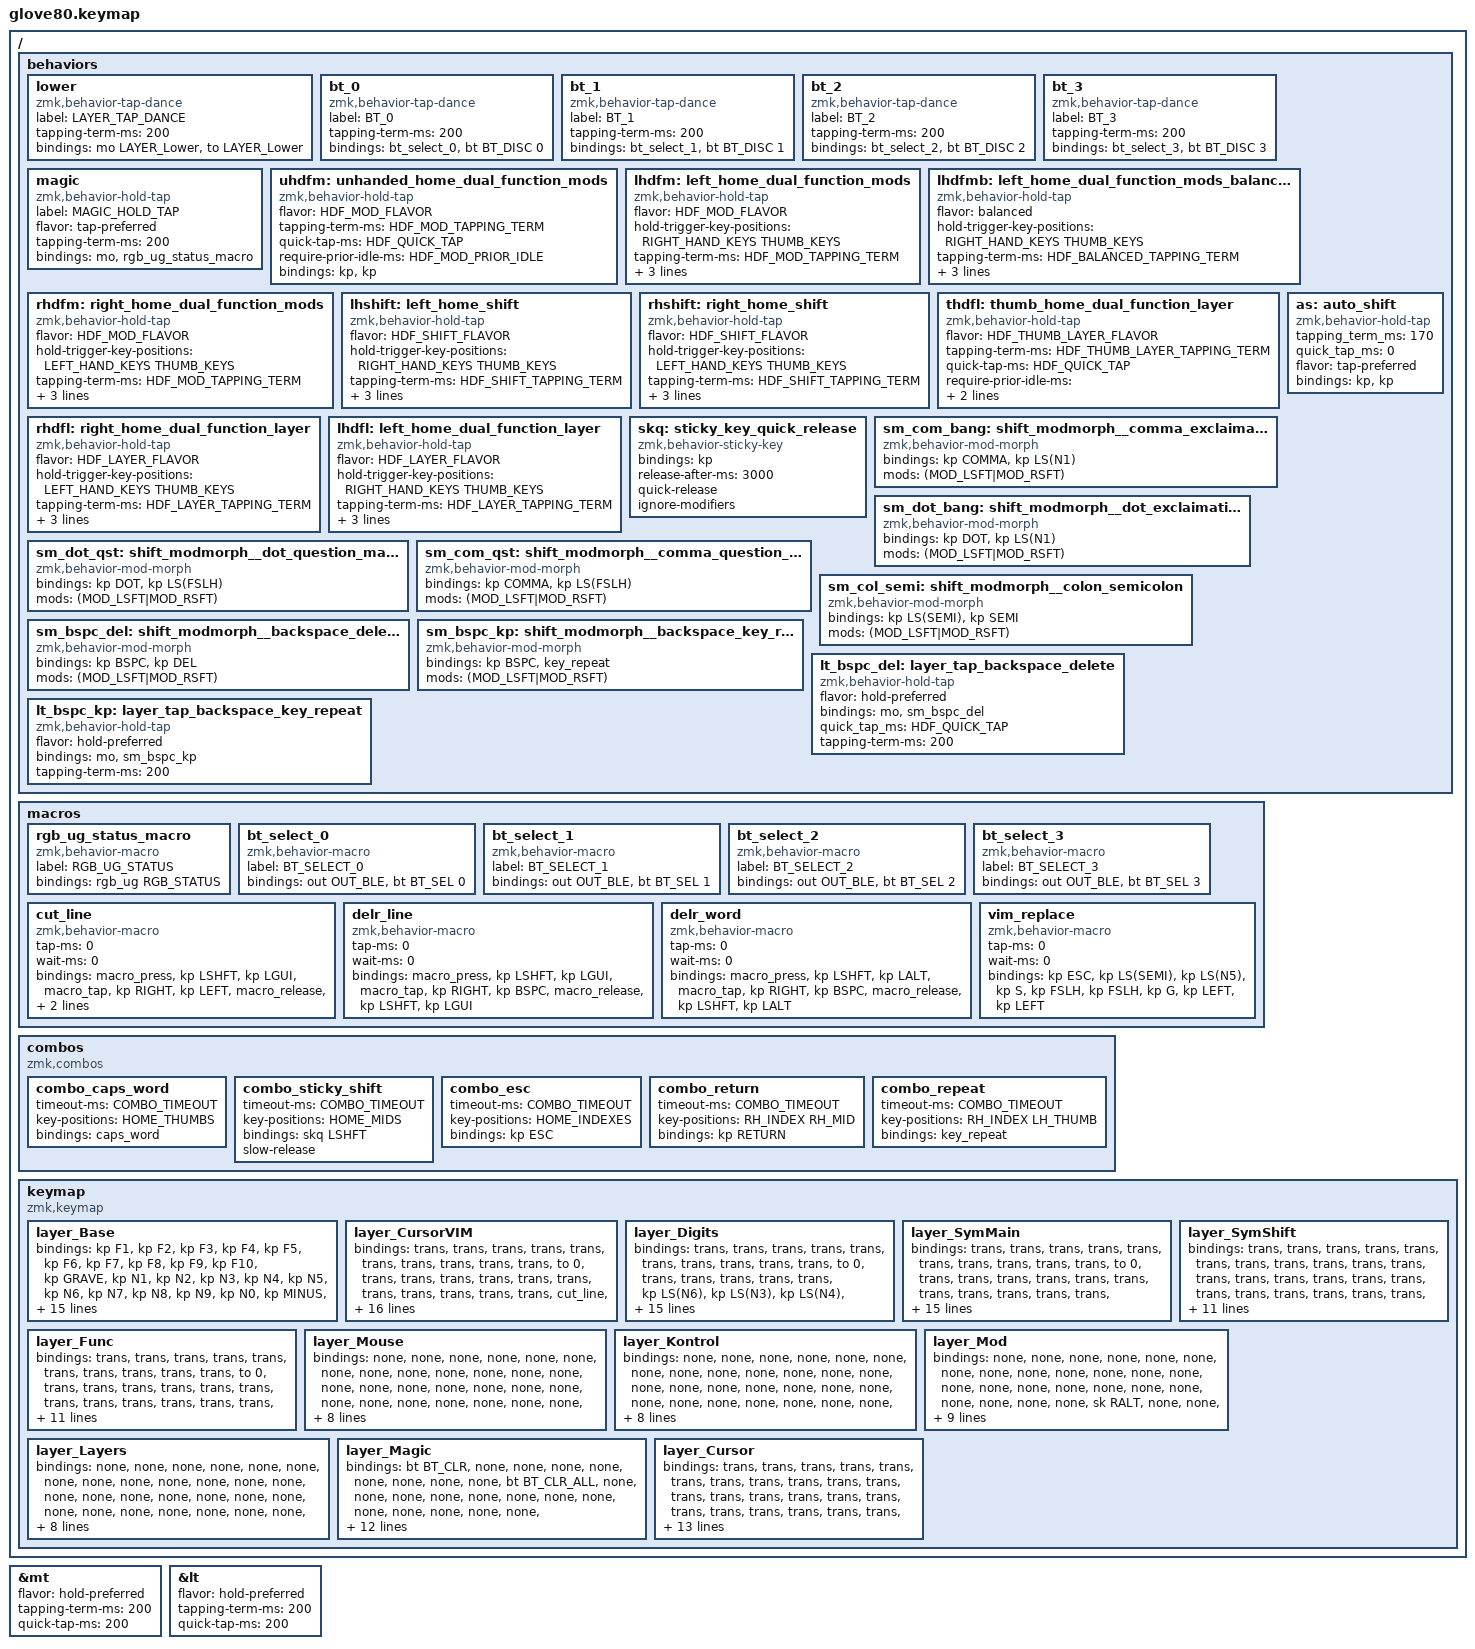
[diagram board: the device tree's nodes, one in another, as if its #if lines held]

/*
 * Copyright (c) 2020 The ZMK Contributors
 * Copyright (c) 2023 Innaworks Development Limited, trading as MoErgo
 *
 * SPDX-License-Identifier: MIT
 */


/* THIS FILE WAS GENERATED BY GLOVE80 LAYOUT EDITOR
 *
 * This file was generated automatically. You may or may not want to
 * edit it directly.
 */

#include <behaviors.dtsi>
#include <dt-bindings/zmk/ext_power.h>
#include <dt-bindings/zmk/outputs.h>
#include <dt-bindings/zmk/keys.h>
#include <dt-bindings/zmk/bt.h>
#include <dt-bindings/zmk/rgb.h>

/* Automatically generated layer name #define */
#define LAYER_Base 0
#define LAYER_CursorVIM 1
#define LAYER_Digits 2
#define LAYER_SymMain 3
#define LAYER_SymShift 4
#define LAYER_Func 5
#define LAYER_Mouse 6
#define LAYER_Kontrol 7
#define LAYER_Mod 8
#define LAYER_Layers 9
#define LAYER_Magic 10
#define LAYER_Cursor 11

/* To deal with the situation where there is no Lower layer, to keep &lower happy */
#ifndef LAYER_Lower
#define LAYER_Lower 0
#endif

/* Custom Device-tree */
&mt {
    flavor = "hold-preferred";
    tapping-term-ms = <200>;
    quick-tap-ms = <200>;
};


// Make layers more responsive for some less used keys.
&lt {
    flavor = "hold-preferred";
    tapping-term-ms = <200>;
    quick-tap-ms = <200>;
};
// NOTE: right shifted underscore seems to disable caps_word
// &caps_word {
//    mods = <(MOD_LSFT | MOD_RSHFT)>;
// };

// NOTE: RGB_STATUS appears to be a defined only
// in the moergo zmk fork.
#ifndef RGB_STATUS_CMD
#define RGB_STATUS_CMD 15
#endif
#ifndef RGB_STATUS
#define RGB_STATUS RGB_STATUS_CMD 0
#endif


/* Glove80 system behavior & macros */
/ {
    behaviors {
        // For the "layer" key, it'd nice to be able to use it as either a shift or a toggle.
        // Configure it as a tap dance, so the first tap (or hold) is a &mo and the second tap is a &to
        lower: lower {
            compatible = "zmk,behavior-tap-dance";
            label = "LAYER_TAP_DANCE";
            #binding-cells = <0>;
            tapping-term-ms = <200>;
            bindings = <&mo LAYER_Lower>, <&to LAYER_Lower>;
        };
    };
};

/ {
    macros {
        rgb_ug_status_macro: rgb_ug_status_macro {
            label = "RGB_UG_STATUS";
            compatible = "zmk,behavior-macro";
            #binding-cells = <0>;
            bindings
                = <&rgb_ug RGB_STATUS>;
        };
    };
};


/ {
#ifdef BT_DISC_CMD
    behaviors {
        bt_0: bt_0 {
            compatible = "zmk,behavior-tap-dance";
            label = "BT_0";
            #binding-cells = <0>;
            tapping-term-ms = <200>;
            bindings = <&bt_select_0>, <&bt BT_DISC 0>;
        };
        bt_1: bt_1 {
            compatible = "zmk,behavior-tap-dance";
            label = "BT_1";
            #binding-cells = <0>;
            tapping-term-ms = <200>;
            bindings = <&bt_select_1>, <&bt BT_DISC 1>;
        };
        bt_2: bt_2 {
            compatible = "zmk,behavior-tap-dance";
            label = "BT_2";
            #binding-cells = <0>;
            tapping-term-ms = <200>;
            bindings = <&bt_select_2>, <&bt BT_DISC 2>;
        };
        bt_3: bt_3 {
            compatible = "zmk,behavior-tap-dance";
            label = "BT_3";
            #binding-cells = <0>;
            tapping-term-ms = <200>;
            bindings = <&bt_select_3>, <&bt BT_DISC 3>;
        };
    };
    macros {
        bt_select_0: bt_select_0 {
            label = "BT_SELECT_0";
            compatible = "zmk,behavior-macro";
            #binding-cells = <0>;
            bindings
                = <&out OUT_BLE>,
                  <&bt BT_SEL 0>;
        };
        bt_select_1: bt_select_1 {
            label = "BT_SELECT_1";
            compatible = "zmk,behavior-macro";
            #binding-cells = <0>;
            bindings
                = <&out OUT_BLE>,
                  <&bt BT_SEL 1>;
        };
        bt_select_2: bt_select_2 {
            label = "BT_SELECT_2";
            compatible = "zmk,behavior-macro";
            #binding-cells = <0>;
            bindings
                = <&out OUT_BLE>,
                  <&bt BT_SEL 2>;
        };
        bt_select_3: bt_select_3 {
            label = "BT_SELECT_3";
            compatible = "zmk,behavior-macro";
            #binding-cells = <0>;
            bindings
                = <&out OUT_BLE>,
                  <&bt BT_SEL 3>;
        };
    };
#else
    macros {
        bt_0: bt_0 {
            label = "BT_0";
            compatible = "zmk,behavior-macro";
            #binding-cells = <0>;
            bindings
                = <&out OUT_BLE>,
                  <&bt BT_SEL 0>;
        };
        bt_1: bt_1 {
            label = "BT_1";
            compatible = "zmk,behavior-macro";
            #binding-cells = <0>;
            bindings
                = <&out OUT_BLE>,
                  <&bt BT_SEL 1>;
        };
        bt_2: bt_2 {
            label = "BT_2";
            compatible = "zmk,behavior-macro";
            #binding-cells = <0>;
            bindings
                = <&out OUT_BLE>,
                  <&bt BT_SEL 2>;
        };
        bt_3: bt_3 {
            label = "BT_3";
            compatible = "zmk,behavior-macro";
            #binding-cells = <0>;
            bindings
                = <&out OUT_BLE>,
                  <&bt BT_SEL 3>;
        };
    };
#endif
};

/ {
    behaviors {
        magic: magic {
            compatible = "zmk,behavior-hold-tap";
            label = "MAGIC_HOLD_TAP";
            #binding-cells = <2>;
            flavor = "tap-preferred";
            tapping-term-ms = <200>;
            bindings = <&mo>, <&rgb_ug_status_macro>;
        };
    };
};

/* #define for key positions */
#define POS_LH_T1 52
#define POS_LH_T2 53
#define POS_LH_T3 54
#define POS_LH_T4 69
#define POS_LH_T5 70
#define POS_LH_T6 71
#define POS_LH_C1R2 15
#define POS_LH_C1R3 27
#define POS_LH_C1R4 39
#define POS_LH_C1R5 51
#define POS_LH_C2R1 4
#define POS_LH_C2R2 14
#define POS_LH_C2R3 26
#define POS_LH_C2R4 38
#define POS_LH_C2R5 50
#define POS_LH_C2R6 68
#define POS_LH_C3R1 3
#define POS_LH_C3R2 13
#define POS_LH_C3R3 25
#define POS_LH_C3R4 37
#define POS_LH_C3R5 49
#define POS_LH_C3R6 67
#define POS_LH_C4R1 2
#define POS_LH_C4R2 12
#define POS_LH_C4R3 24
#define POS_LH_C4R4 36
#define POS_LH_C4R5 48
#define POS_LH_C4R6 66
#define POS_LH_C5R1 1
#define POS_LH_C5R2 11
#define POS_LH_C5R3 23
#define POS_LH_C5R4 35
#define POS_LH_C5R5 47
#define POS_LH_C5R6 65
#define POS_LH_C6R1 0
#define POS_LH_C6R2 10
#define POS_LH_C6R3 22
#define POS_LH_C6R4 34
#define POS_LH_C6R5 46
#define POS_LH_C6R6 64
#define POS_RH_T1 57
#define POS_RH_T2 56
#define POS_RH_T3 55
#define POS_RH_T4 74
#define POS_RH_T5 73
#define POS_RH_T6 72
#define POS_RH_C1R2 16
#define POS_RH_C1R3 28
#define POS_RH_C1R4 40
#define POS_RH_C1R5 58
#define POS_RH_C2R1 5
#define POS_RH_C2R2 17
#define POS_RH_C2R3 29
#define POS_RH_C2R4 41
#define POS_RH_C2R5 59
#define POS_RH_C2R6 75
#define POS_RH_C3R1 6
#define POS_RH_C3R2 18
#define POS_RH_C3R3 30
#define POS_RH_C3R4 42
#define POS_RH_C3R5 60
#define POS_RH_C3R6 76
#define POS_RH_C4R1 7
#define POS_RH_C4R2 19
#define POS_RH_C4R3 31
#define POS_RH_C4R4 43
#define POS_RH_C4R5 61
#define POS_RH_C4R6 77
#define POS_RH_C5R1 8
#define POS_RH_C5R2 20
#define POS_RH_C5R3 32
#define POS_RH_C5R4 44
#define POS_RH_C5R5 62
#define POS_RH_C5R6 78
#define POS_RH_C6R1 9
#define POS_RH_C6R2 21
#define POS_RH_C6R3 33
#define POS_RH_C6R4 45
#define POS_RH_C6R5 63
#define POS_RH_C6R6 79

    /* Custom Defined Behaviors */
/ {
    // Custom Defined Behaviors dtsi snippets.
// These snippets are included by the online configurator in as / {}; block in
// the resulting keymap fie. Include behaviors, combos, and macros.
//
// Device tree configs, e.g., for mt and lt should go in the Device Tree text
// block.
//
// ---------------------------------------------------------------------------
// TODOS:
// - [ ] key repeat on a dedicated key, layer, combo, or shift mod-morph if possible.
//       As shift morph-mod, it likely picks up on shift and does nothing.
// - [ ] shift mod-morph backspace, delete.
// - [ ] tab on a layer, combo, or shift mod-morph if possible.
// - [ ] Right hand symbol / punc layer.
// - [ ] Right hand symbol / punc layer.
// ---------------------------------------------------------------------------
// Glove80 key positions index for positional hold-tap
// - https://discord.com/channels/877392805654306816/937645688244826154/1066713913351221248
// When the keymap file is compiled by the online configurator, it defines
// position keys like `POS_{hand}_{column}{row}`, e.g. `POS_LH_C1R2`
// Thumb keys follow `POS_{hand}_{index}` with T1 and T4
// denoting the innermost thumbs on the upper and home thumb cluster, resp.
//
// |------------|-------------------------|--------------------------|
// |            | LEFT_HAND_KEYS          |          RIGHT_HAND_KEYS |
// |------------|-------------------------|--------------------------|
// | row | name | C6 C5 C4 C3 C2 C1       |        C1 C2 C3 C4 C5 C6 |
// |-----|------|-------------------------|--------------------------|
// | R1  | fn   |  0  1  2  3  4          |            5  6  7  8  9 |
// | R2  | num  | 10 11 12 13 14 15       |        16 17 18 19 20 21 |
// | R3  | up   | 22 23 24 25 26 27       |        28 29 30 31 32 33 |
// | R4  | home | 34 35 36 37 38 39       |        40 41 42 43 44 45 |
// | R5  | down | 46 47 48 49 50 51       |        58 59 60 61 62 63 |
// | R6  | bot  | 64 65 66 67 68          |           75 76 77 78 79 |
// |------------|-------------------------|--------------------------|
// | thumb top  |                52 53 54 |  55 56 57                |
// | thumb lower|                69 70 71 |  72 73 74                |
// |------------|-------------------------|--------------------------|
// | thumb name |                T1 T2 T3 |  T3 T2 T1                |
// |            |                T4 T4 T6 |  T6 T5 T4                |
// |------------|-------------------------|--------------------------|

// Keys used to define bilaterial home modifiers.
#define LEFT_HAND_KEYS \
     0  1  2  3  4     \
    10 11 12 13 14 15  \
    22 23 24 25 26 27  \
    34 35 36 37 38 39  \
    46 47 48 49 50 51  \
    64 65 66 67 68

#define RIGHT_HAND_KEYS \
       5  6  7  8  9    \
   16 17 18 19 20 21    \
   28 29 30 31 32 33    \
   40 41 42 43 44 45    \
   58 59 60 61 62 63    \
      75 76 77 78 79

#define THUMB_KEYS       \
    52 53 54    55 56 57 \
    69 70 71    72 73 74

#define THUMB_KEYS_WITHOUT_SPACE  \
    52 53 54    55 56 57 \
    69 70 71    72 73

// Named fingers for homerow combos.
#define LH_INDEX     38
#define LH_MID       37
#define LH_RING      36
#define LH_PINKY     35
#define LH_THUMB     69
#define RH_INDEX     41
#define RH_MID       42
#define RH_RING      43
#define RH_PINKY     44
#define RH_THUMB     74
#define HOME_INDEXES 38 41
#define HOME_MIDS    37 42
#define HOME_RINGS   36 43
#define HOME_PINKIES 35 44
#define HOME_THUMBS  69 74

// Hold flavor enums.
#define BALANCED  0
#define INTERRUPT 1
#define HOLDPREF  2
#define TAPPREF   3

// Default timing.
#define COMBO_PRIOR_IDLE 150
#define COMBO_TIMEOUT 50
#define HDF_TAPPING_TERM 250
#define HDF_QUICK_TAP 200
#define HDF_BALANCED_PRIOR_IDLE 125
#define HDF_BALANCED_TAPPING_TERM 175
#define HDF_INTERRUPT_PRIOR_IDLE 250
#define HDF_INTERRUPT_TAPPING_TERM 250

// Frequently used dual function keys, e.g., base layer
// homerow and space keys. Less often used keys will utilize standard
// mod-tap and layer-tap nodes (mt and lt, resp.)
// We distinguish between the following categories
// - homerow mods other than shift
// - homerow shift
// - homerow layers
// - thumb layers
// NOTE: hold-trigger-on-release can cause misfires, but it is the
// only simple way to allow simultaneous bilaterial homerow mods.
// In this configuration, multiple home modifiers are present in layers
// such as the cursor and symbol layers.
#define HDF_MOD_STYLE         BALANCED
#define HDF_SHIFT_STYLE       INTERRUPT
#define HDF_LAYER_STYLE       BALANCED
#define HDF_THUMB_LAYER_STYLE BALANCED
#if (HDF_SHIFT_STYLE == BALANCED)
    #define HDF_SHIFT_FLAVOR            "balanced"
    #define HDF_SHIFT_PRIOR_IDLE        HDF_BALANCED_PRIOR_IDLE
    #define HDF_SHIFT_TAPPING_TERM      HDF_BALANCED_TAPPING_TERM
#elif (HDF_SHIFT_STYLE == INTERRUPT)
    #define HDF_SHIFT_FLAVOR            "tap-unless-interrupted"
    #define HDF_SHIFT_PRIOR_IDLE        HDF_INTERRUPT_PRIOR_IDLE
    #define HDF_SHIFT_TAPPING_TERM      HDF_INTERRUPT_TAPPING_TERM
#endif
#if (HDF_MOD_STYLE == BALANCED)
    #define HDF_MOD_FLAVOR               "balanced"
    #define HDF_MOD_PRIOR_IDLE           HDF_BALANCED_PRIOR_IDLE
    #define HDF_MOD_TAPPING_TERM         HDF_BALANCED_TAPPING_TERM
#elif (HDF_MOD_STYLE == INTERRUPT)
    #define HDF_MOD_FLAVOR               "tap-unless-interrupted"
    #define HDF_MOD_PRIOR_IDLE           HDF_INTERRUPT_PRIOR_IDLE
    #define HDF_MOD_TAPPING_TERM         HDF_INTERRUPT_TAPPING_TERM
#endif
#if (HDF_LAYER_STYLE == BALANCED)
    #define HDF_LAYER_FLAVOR             "balanced"
    #define HDF_LAYER_PRIOR_IDLE         HDF_BALANCED_PRIOR_IDLE
    #define HDF_LAYER_TAPPING_TERM       HDF_BALANCED_TAPPING_TERM
#elif (HDF_LAYER_STYLE == INTERRUPT)
    #define HDF_LAYER_FLAVOR             "tap-unless-interrupted"
    #define HDF_LAYER_PRIOR_IDLE         HDF_INTERRUPT_PRIOR_IDLE
    #define HDF_LAYER_TAPPING_TERM       HDF_INTERRUPT_TAPPING_TERM
#endif
#if (HDF_THUMB_LAYER_STYLE == BALANCED)
    #define HDF_THUMB_LAYER_FLAVOR       "balanced"
    #define HDF_THUMB_LAYER_PRIOR_IDLE   HDF_BALANCED_PRIOR_IDLE
    #define HDF_THUMB_LAYER_TAPPING_TERM HDF_BALANCED_TAPPING_TERM
#elif (HDF_THUMB_LAYER_STYLE == INTERRUPT)
    #define HDF_THUMB_LAYER_FLAVOR       "tap-unless-interrupted"
    #define HDF_THUMB_LAYER_PRIOR_IDLE   HDF_INTERRUPT_PRIOR_IDLE
    #define HDF_THUMB_LAYER_TAPPING_TERM HDF_INTERRUPT_TAPPING_TERM
#endif

    behaviors {

        // ---------------------------------------------------------------------
        // Home dual function mod and layer behaviors.
        //
        // ---------------------------------------------------------------------
        // Unhanded dual function modifier keys with a balanced flavor.
        // For example, space key with alt, ctrl, gui on hold.
        uhdfm: unhanded_home_dual_function_mods {
            compatible = "zmk,behavior-hold-tap";
            #binding-cells = <2>;
            flavor = HDF_MOD_FLAVOR;
            tapping-term-ms = <HDF_MOD_TAPPING_TERM>;
            quick-tap-ms = <HDF_QUICK_TAP>;
            require-prior-idle-ms = <HDF_MOD_PRIOR_IDLE>;
            bindings = <&kp>, <&kp>;
        };

        // Left dual function modifier keys.
        // For example, homerow mods for alt, ctrl, gui.
        lhdfm: left_home_dual_function_mods {
            compatible = "zmk,behavior-hold-tap";
            #binding-cells = <2>;
            flavor = HDF_MOD_FLAVOR;
            hold-trigger-key-positions = <RIGHT_HAND_KEYS THUMB_KEYS>;
            // hold-trigger-on-release;
            tapping-term-ms = <HDF_MOD_TAPPING_TERM>;
            quick-tap-ms = <HDF_QUICK_TAP>;
            require-prior-idle-ms = <HDF_MOD_PRIOR_IDLE>;
            bindings = <&kp>, <&kp>;
        };

        lhdfmb: left_home_dual_function_mods_balanced {
            compatible = "zmk,behavior-hold-tap";
            #binding-cells = <2>;
            flavor = "balanced";
            hold-trigger-key-positions = <RIGHT_HAND_KEYS THUMB_KEYS>;
            // hold-trigger-on-release;
            tapping-term-ms = <HDF_BALANCED_TAPPING_TERM>;
            quick-tap-ms = <HDF_QUICK_TAP>;
            require-prior-idle-ms = <HDF_BALANCED_PRIOR_IDLE>;
            bindings = <&kp>, <&kp>;
        };

        // Right dual function modifier keys.
        // For example, homerow mods for shift, alt, ctrl, gui.
        rhdfm: right_home_dual_function_mods {
            compatible = "zmk,behavior-hold-tap";
            #binding-cells = <2>;
            flavor = HDF_MOD_FLAVOR;
            hold-trigger-key-positions = <LEFT_HAND_KEYS THUMB_KEYS>;
            // hold-trigger-on-release;
            tapping-term-ms = <HDF_MOD_TAPPING_TERM>;
            quick-tap-ms = <HDF_QUICK_TAP>;
            require-prior-idle-ms = <HDF_MOD_PRIOR_IDLE>;
            bindings = <&kp>, <&kp>;
        };

        lhshift: left_home_shift {
            compatible = "zmk,behavior-hold-tap";
            #binding-cells = <2>;
            flavor = HDF_SHIFT_FLAVOR;
            hold-trigger-key-positions = <RIGHT_HAND_KEYS THUMB_KEYS>;
            // hold-trigger-on-release;
            tapping-term-ms = <HDF_SHIFT_TAPPING_TERM>;
            quick-tap-ms = <HDF_QUICK_TAP>;
            require-prior-idle-ms = <HDF_SHIFT_PRIOR_IDLE>;
            bindings = <&kp>, <&kp>;
        };

        rhshift: right_home_shift {
            compatible = "zmk,behavior-hold-tap";
            #binding-cells = <2>;
            flavor = HDF_SHIFT_FLAVOR;
            hold-trigger-key-positions = <LEFT_HAND_KEYS THUMB_KEYS>;
            // hold-trigger-on-release;
            tapping-term-ms = <HDF_SHIFT_TAPPING_TERM>;
            quick-tap-ms = <HDF_QUICK_TAP>;
            require-prior-idle-ms = <HDF_SHIFT_PRIOR_IDLE>;
            bindings = <&kp>, <&kp>;
        };

        // Dual function layer keys on the thumbs, such as space.
        thdfl: thumb_home_dual_function_layer {
            compatible = "zmk,behavior-hold-tap";
            #binding-cells = <2>;
            flavor = HDF_THUMB_LAYER_FLAVOR;
            tapping-term-ms = <HDF_THUMB_LAYER_TAPPING_TERM>;
            quick-tap-ms = <HDF_QUICK_TAP>;
            require-prior-idle-ms = <HDF_THUMB_LAYER_PRIOR_IDLE>;
            bindings = <&mo>, <&kp>;
        };

        // Right home dual function layer keys.
        rhdfl: right_home_dual_function_layer {
            compatible = "zmk,behavior-hold-tap";
            #binding-cells = <2>;
            flavor = HDF_LAYER_FLAVOR;
            hold-trigger-key-positions = <LEFT_HAND_KEYS THUMB_KEYS>;
            tapping-term-ms = <HDF_LAYER_TAPPING_TERM>;
            quick-tap-ms = <HDF_QUICK_TAP>;
            require-prior-idle-ms = <HDF_LAYER_PRIOR_IDLE>;
            bindings = <&mo>, <&kp>;
        };

        // Left home dual function layer keys.
        lhdfl: left_home_dual_function_layer {
            compatible = "zmk,behavior-hold-tap";
            #binding-cells = <2>;
            flavor = HDF_LAYER_FLAVOR;
            hold-trigger-key-positions = <RIGHT_HAND_KEYS THUMB_KEYS>;
            tapping-term-ms = <HDF_LAYER_TAPPING_TERM>;
            quick-tap-ms = <HDF_QUICK_TAP>;
            require-prior-idle-ms = <HDF_LAYER_PRIOR_IDLE>;
            bindings = <&mo>, <&kp>;
        };

        // Auto "shift" allows a second keypress upon a short hold.
        as: auto_shift {
            compatible = "zmk,behavior-hold-tap";
            #binding-cells = <2>;
            tapping_term_ms = <170>;
            quick_tap_ms = <0>;
            flavor = "tap-preferred";
            bindings = <&kp>, <&kp>;
        };

        // Sticky key that lasts only one key press.
        skq: sticky_key_quick_release {
            compatible = "zmk,behavior-sticky-key";
            #binding-cells = <1>;
            bindings = <&kp>;
            release-after-ms = <3000>;
            quick-release;
            ignore-modifiers;
        };

        // ---------------------------------------------------------------------
        // mod-morphs
        // ---------------------------------------------------------------------
        // Shifted mod-morphs where second kp
        sm_com_bang: shift_modmorph__comma_exclaimation {
            compatible = "zmk,behavior-mod-morph";
            #binding-cells = <0>;
            bindings = <&kp COMMA>, <&kp LS(N1)>;
            mods = <(MOD_LSFT|MOD_RSFT)>;
        };

        sm_dot_bang: shift_modmorph__dot_exclaimation {
            compatible = "zmk,behavior-mod-morph";
            #binding-cells = <0>;
            bindings = <&kp DOT>, <&kp LS(N1)>;
            mods = <(MOD_LSFT|MOD_RSFT)>;
        };

        // shift+. -> ?
        sm_dot_qst: shift_modmorph__dot_question_mark {
            compatible = "zmk,behavior-mod-morph";
            #binding-cells = <0>;
            bindings = <&kp DOT>, <&kp LS(FSLH)>;
            mods = <(MOD_LSFT|MOD_RSFT)>;
        };

        // shift+, -> ?
        sm_com_qst: shift_modmorph__comma_question_mark {
            compatible = "zmk,behavior-mod-morph";
            #binding-cells = <0>;
            bindings = <&kp COMMA>, <&kp LS(FSLH)>;
            mods = <(MOD_LSFT|MOD_RSFT)>;
        };

        // Key with colon and semicolon in swapped shift order.
        sm_col_semi: shift_modmorph__colon_semicolon {
            compatible = "zmk,behavior-mod-morph";
            #binding-cells = <0>;
            bindings = <&kp LS(SEMI)>, <&kp SEMI>;
            mods = <(MOD_LSFT|MOD_RSFT)>;
        };

        sm_bspc_del: shift_modmorph__backspace_delete {
            compatible = "zmk,behavior-mod-morph";
            #binding-cells = <0>;
            bindings = <&kp BSPC>, <&kp DEL>;
            mods = <(MOD_LSFT|MOD_RSFT)>;
        };

        // unclear if this actually works. Does not appear so in an lt behavior.
        sm_bspc_kp: shift_modmorph__backspace_key_repeat {
            compatible = "zmk,behavior-mod-morph";
            #binding-cells = <0>;
            bindings = <&kp BSPC>, <&key_repeat>;
            mods = <(MOD_LSFT|MOD_RSFT)>;
        };

        // Layer tap on a backspace-delete shift mod-morph
        lt_bspc_del: layer_tap_backspace_delete {
            compatible = "zmk,behavior-hold-tap";
            flavor = "hold-preferred";
            #binding-cells = <2>;
            bindings = <&mo>, <&sm_bspc_del>;
            quick_tap_ms = <HDF_QUICK_TAP>;
            tapping-term-ms = <200>;
        };

        // Layer tap on a backspace-repeat shift mod-morph
        lt_bspc_kp: layer_tap_backspace_key_repeat {
            compatible = "zmk,behavior-hold-tap";
            flavor = "hold-preferred";
            #binding-cells = <2>;
            bindings = <&mo>, <&sm_bspc_kp>;
            tapping-term-ms = <200>;
        };
    };


    macros {

        // Delete and yank current line.
        cut_line: cut_line {
            compatible = "zmk,behavior-macro";
            tap-ms = <0>;
            wait-ms = <0>;
            #binding-cells = <0>;
            bindings
                = <&macro_press &kp LSHFT &kp LGUI>
                , <&macro_tap &kp RIGHT &kp LEFT>
                , <&macro_release &kp LSHFT>
                , <&macro_tap &kp K>
                , <&macro_release &kp LGUI>
                ;
        };

        delr_line: delr_line {
            compatible = "zmk,behavior-macro";
            tap-ms = <0>;
            wait-ms = <0>;
            #binding-cells = <0>;
            bindings
                = <&macro_press &kp LSHFT &kp LGUI>
                , <&macro_tap &kp RIGHT &kp BSPC>
                , <&macro_release &kp LSHFT &kp LGUI>
                ;
        };

        delr_word: delr_word {
            compatible = "zmk,behavior-macro";
            tap-ms = <0>;
            wait-ms = <0>;
            #binding-cells = <0>;
            bindings
                = <&macro_press &kp LSHFT &kp LALT>
                , <&macro_tap &kp RIGHT &kp BSPC>
                , <&macro_release &kp LSHFT &kp LALT>
                ;
        };

        vim_replace: vim_replace {
            compatible = "zmk,behavior-macro";
            tap-ms = <0>;
            wait-ms = <0>;
            #binding-cells = <0>;
            bindings
                = <&kp ESC &kp LS(SEMI) &kp LS(N5) &kp S &kp FSLH &kp FSLH &kp G>
                , <&kp LEFT &kp LEFT>
                ;
        };
    };

    combos {
        compatible = "zmk,combos";

        combo_caps_word {
            timeout-ms = <COMBO_TIMEOUT>;
            key-positions = <HOME_THUMBS>;
            // require-prior-idle-ms = <COMBO_PRIOR_IDLE>;
            bindings = <&caps_word>;
        };

        combo_sticky_shift {
            timeout-ms = <COMBO_TIMEOUT>;
            key-positions = <HOME_MIDS>;
            // require-prior-idle-ms = <COMBO_PRIOR_IDLE>;
            bindings = <&skq LSHFT>;
            slow-release;
        };

        combo_esc {
            timeout-ms = <COMBO_TIMEOUT>;
            key-positions = <HOME_INDEXES>;
            // require-prior-idle-ms = <COMBO_PRIOR_IDLE>;
            bindings = <&kp ESC>;
        };

        combo_return {
            timeout-ms = <COMBO_TIMEOUT>;
            key-positions = <RH_INDEX RH_MID>;
            // require-prior-idle-ms = <COMBO_PRIOR_IDLE>;
            bindings = <&kp RETURN>;
        };

        combo_repeat {
            timeout-ms = <COMBO_TIMEOUT>;
            key-positions = <RH_INDEX LH_THUMB>;
            // require-prior-idle-ms = <COMBO_PRIOR_IDLE>;
            bindings = <&key_repeat>;
        };

    };

};

    /* Automatically generated keymap */
/ {
    keymap {
        compatible = "zmk,keymap";


        layer_Base {
            bindings = <
               &kp F1       &kp F2   &kp F3    &kp F4            &kp F5                                                                                                             &kp F6       &kp F7        &kp F8          &kp F9        &kp F10
            &kp GRAVE       &kp N1   &kp N2    &kp N3            &kp N4  &kp N5                                                                                   &kp N6            &kp N7       &kp N8        &kp N9          &kp N0      &kp MINUS
            &kp EQUAL        &kp Q    &kp W     &kp E             &kp R   &kp T                                                                                    &kp Y             &kp U        &kp I         &kp O           &kp P       &kp BSLH
       &mt LGUI MINUS        &kp A    &kp S     &kp D  &lhshift LSHFT F   &kp G                                                                                    &kp H  &rhshift LSHFT J   &rhdfl 4 K         &kp L    &sm_col_semi  &mt LCTRL SQT
            &sk LSHFT  &mt LSHFT Z    &kp X     &kp C             &kp V   &kp B     &mt LSHFT ESC  &skq LSHFT  &kp LALT  &kp RALT       &kp LGUI   &mt LSHFT RET   &kp N             &kp M  &sm_com_qst  &sm_dot_bang  &mt LSHFT FSLH      &kp PG_UP
 &magic LAYER_Magic 0     &kp HOME  &kp END  &kp LEFT         &kp RIGHT          &lt_bspc_del 1 0   &lt 2 DEL     &to 9     &to 2  &mt LSHFT TAB  &thdfl 3 SPACE                  &kp DOWN       &kp UP      &kp LBKT        &kp RBKT      &kp PG_DN
            >;
        };

        layer_CursorVIM {
            bindings = <
     &trans              &trans             &trans              &trans               &trans                                                                                       &trans         &trans            &trans         &trans    &trans
      &to 0              &trans             &trans              &trans               &trans     &trans                                                            &trans          &trans         &trans            &trans         &trans    &trans
  &cut_line        &kp LG(BSPC)     &mt RALT LG(X)           &kp LG(C)            &kp LG(V)  &kp LG(C)                                                         &kp LG(C)       &kp LG(Z)  &kp LG(LS(Z))  &mt RALT LG(TAB)      &kp LG(V)    &trans
 &caps_word  &mt LSHFT LG(LEFT)  &mt LALT LA(LEFT)  &mt LGUI LA(RIGHT)  &mt LCTRL LG(RIGHT)    &kp DEL                                                          &kp LEFT  &mt LCTRL DOWN    &mt LGUI UP    &mt LALT RIGHT  &mt LSHFT RET  &kp BSPC
     &trans    &kp LS(LG(LEFT))   &kp LS(LA(LEFT))   &kp LS(LA(RIGHT))    &kp LS(LG(RIGHT))  &kp LG(X)  &trans  &trans  &trans  &trans  &trans      &kp LG(V)   &kp HOME       &kp PG_DN      &kp PG_UP           &kp END         &trans    &trans
     &trans              &trans             &trans              &trans               &trans             &trans  &trans   &to 0  &trans  &trans  &mt LSHFT RET                     &trans         &trans            &trans         &trans    &trans
            >;
        };

        layer_Digits {
            bindings = <
        &trans        &trans        &trans         &trans           &trans                                                                                               &trans        &trans         &trans        &trans    &trans
         &to 0        &trans        &trans         &trans           &trans      &trans                                                                   &kp LS(N6)  &kp LS(N3)    &kp LS(N4)  &kp LS(GRAVE)        &trans    &trans
 &kp LS(GRAVE)    &kp LS(N1)    &kp LS(N2)     &kp LS(N3)       &kp LS(N4)  &kp LS(N5)                                                              &kp KP_MULTIPLY      &kp N7        &kp N8         &kp N9  &kp KP_SLASH    &trans
 &kp LS(MINUS)  &kp LS(SEMI)    &kp KP_DOT     &kp LS(N9)  &mt LGUI LS(N0)  &kp LS(N6)                                                                  &kp KP_PLUS      &kp N4        &kp N5         &kp N6  &kp KP_MINUS  &kp BSPC
        &trans        &trans  &kp KP_COMMA  &kp LS(COMMA)      &kp LS(DOT)      &trans  &trans  &trans  &trans  &trans        &trans  &kp KP_EQUAL     &kp KP_COMMA      &kp N1        &kp N2         &kp N3    &kp KP_DOT    &trans
        &trans        &trans        &trans         &trans           &trans              &trans  &trans   &to 0  &trans  &kp KP_CLEAR     &kp KP_N0                    &kp KP_N0  &kp KP_COMMA     &kp KP_DOT  &kp KP_ENTER    &trans
            >;
        };

        layer_SymMain {
            bindings = <
        &trans            &trans           &trans              &trans           &trans                                                                                               &trans        &trans      &trans     &trans  &trans
         &to 0            &trans           &trans              &trans           &trans        &trans                                                                   &trans        &trans        &trans      &trans     &trans  &trans
 &kp LS(GRAVE)      &kp LS(FSLH)          &kp SQT         &kp LS(SQT)         &kp FSLH    &kp LS(N1)                                                            &kp LS(EQUAL)    &kp LS(N0)    &kp LS(N9)  &kp LS(N2)   &kp BSPC  &trans
    &kp LS(N3)  &mt LSHFT LS(N6)  &mt LCTRL EQUAL  &mt LALT LS(MINUS)  &mt LGUI LS(N4)    &kp LS(N8)                                                                  &kp DOT  &kp LS(RBKT)  &kp LS(LBKT)  &kp LS(N5)  &kp SPACE  &trans
        &trans     &kp LS(COMMA)     &kp LS(BSLH)           &kp MINUS      &kp LS(DOT)  &kp LS(FSLH)      &kp BSLH      &trans  &trans  &trans  &trans  &trans         &trans      &kp RBKT      &kp LBKT  &kp LS(N7)     &trans  &trans
        &trans            &trans           &trans              &trans           &trans                &kp LS(SEMI)  &kp LS(N5)   &to 0  &trans  &trans  &trans                       &trans        &trans      &trans     &trans  &trans
            >;
        };

        layer_SymShift {
            bindings = <
 &trans         &trans      &trans       &trans      &trans                                                                      &trans  &trans  &trans  &trans  &trans
 &trans         &trans      &trans       &trans      &trans  &trans                                                      &trans  &trans  &trans  &trans  &trans  &trans
 &trans     &kp LS(N1)  &kp LS(N2)   &kp LS(N3)  &kp LS(N4)  &trans                                                      &trans  &trans  &trans  &trans  &trans  &trans
 &trans  &kp LS(GRAVE)     &kp SQT  &kp LS(SQT)   &kp GRAVE  &trans                                                      &trans  &trans  &trans  &trans  &trans  &trans
 &trans         &trans      &trans       &trans      &trans  &trans    &trans  &trans  &trans  &trans  &trans    &trans  &trans  &trans  &trans  &trans  &trans  &trans
 &trans         &trans      &trans       &trans      &trans          &kp FSLH  &trans  &trans  &trans  &trans  &kp FSLH          &trans  &trans  &trans  &trans  &trans
            >;
        };

        layer_Func {
            bindings = <
 &trans        &trans        &trans         &trans         &trans                                                                  &trans  &trans  &trans   &trans   &trans
  &to 0        &trans        &trans         &trans         &trans  &trans                                                  &trans  &trans  &trans  &trans   &trans   &trans
 &trans       &kp F22  &mt RALT F19        &kp F20        &kp F21  &trans                                                  &trans  &kp F7  &kp F8  &kp F9  &kp F10  &kp F13
 &trans  &mt LGUI F23  &mt LALT F16  &mt LCTRL F17  &mt GLOBE F18  &trans                                                  &trans  &kp F4  &kp F5  &kp F6  &kp F11  &kp F14
 &trans       &kp F24       &kp F13        &kp F14        &kp F15  &trans  &trans  &trans  &trans  &trans  &trans  &trans  &trans  &kp F1  &kp F2  &kp F3  &kp F12  &kp F15
 &trans        &trans        &trans         &trans         &trans          &trans  &trans   &to 0  &trans  &trans  &trans          &trans  &trans  &trans   &trans   &trans
            >;
        };

        layer_Mouse {
            bindings = <
  &none   &none   &none   &none   &none                                                                   &none              &none   &none   &none   &none
  &none   &none   &none   &none   &none   &none                                                   &none   &none              &none   &none   &none   &none
  &none   &none   &none   &none   &none   &none                                                   &none   &none              &none   &none   &none   &none
  &to 0   &none   &none   &none   &none   &none                                                   &none   &none  &kp K_SCROLL_DOWN   &none   &none   &none
  &none   &none   &none   &none   &none   &none   &none   &none   &none   &none   &none   &none   &none   &none              &none   &none   &none   &none
  &none   &none   &none   &none   &none           &none   &none   &none   &none   &none   &none           &none              &none   &none   &none   &none
            >;
        };

        layer_Kontrol {
            bindings = <
  &none   &none   &none   &none   &none                                                                   &none   &none   &none   &none   &none
  &none   &none   &none   &none   &none   &none                                                   &none   &none   &none   &none   &none   &none
  &none   &none   &none   &none   &none   &none                                                   &none   &none   &none   &none   &none   &none
  &none   &none   &none   &none   &none   &none                                                   &none   &none   &none   &none   &none   &none
  &none   &none   &none   &none   &none   &none   &none   &none   &none   &none   &none   &none   &none   &none   &none   &none   &none   &none
  &none   &none   &none   &none   &none           &none   &none   &to 0   &none   &none   &none           &none   &none   &none   &none   &none
            >;
        };

        layer_Mod {
            bindings = <
  &none     &none     &none      &none       &none                                                                         &none      &none     &none     &none   &none
  &none     &none     &none      &none       &none   &none                                                       &none     &none      &none     &none     &none   &none
  &none     &none  &sk RALT      &none       &none   &none                                                       &none     &none      &none  &sk RALT     &none   &none
  &to 0  &sk LGUI  &sk LALT  &sk LCTRL  &caps_word   &none                                                       &none  &sk RGUI  &sk RCTRL  &sk LALT  &sk RGUI   &none
  &none     &none     &none      &none       &none   &none    &none   &none   &none   &none   &none      &none   &none     &none      &none     &none     &none   &none
  &none     &none     &none      &none       &none          &kp ESC   &none   &none   &none   &none  &sk LCTRL             &none      &none     &none     &none   &none
            >;
        };

        layer_Layers {
            bindings = <
  &none   &none   &none   &none   &none                                                                   &none   &none   &none   &none   &none
  &none   &none   &none   &none   &none   &none                                                   &none   &none   &none   &none   &none   &none
  &none   &none   &none   &none   &none   &none                                                   &none   &none   &none   &none   &none   &none
  &none   &none   &to 3   &to 2   &to 5   &none                                                   &none   &none   &to 7   &none   &none   &none
  &none   &none   &none  &to 11   &to 1   &none   &none   &none   &none   &none   &none   &none   &none   &none   &none   &none   &none   &none
  &none   &none   &none   &none   &none           &none   &none   &to 0   &none   &none   &none           &none   &none   &none   &none   &none
            >;
        };

        layer_Magic {
            bindings = <
  &bt BT_CLR            &none            &none            &none            &none                                                                                  &none   &none   &none   &none  &bt BT_CLR_ALL
       &none            &none            &none            &none            &none            &none                                                         &none   &none   &none   &none   &none           &none
       &none  &rgb_ug RGB_SPI  &rgb_ug RGB_SAI  &rgb_ug RGB_HUI  &rgb_ug RGB_BRI  &rgb_ug RGB_TOG                                                         &none   &none   &none   &none   &none           &none
 &bootloader  &rgb_ug RGB_SPD  &rgb_ug RGB_SAD  &rgb_ug RGB_HUD  &rgb_ug RGB_BRD  &rgb_ug RGB_EFF                                                         &none   &none   &none   &none   &none     &bootloader
  &sys_reset            &none            &none            &none            &none            &none   &bt_2   &bt_3         &none   &none   &none   &none   &none   &none   &none   &none   &none      &sys_reset
       &none            &none            &none            &none            &none                    &bt_0   &bt_1  &out OUT_USB   &none   &none   &none           &none   &none   &none   &none           &none
            >;
        };

        layer_Cursor {
            bindings = <
 &trans              &trans          &trans         &trans          &trans                                                                                        &trans          &trans          &trans        &trans  &trans
 &trans              &trans          &trans         &trans          &trans      &trans                                                           &trans           &trans          &trans          &trans        &trans  &trans
 &trans              &trans        &kp RALT         &trans    &kp LA(BSPC)      &trans                                                           &trans         &kp HOME          &kp UP    &mt RALT END        &trans  &trans
  &to 0  &mt LGUI LG(SPACE)  &mt LALT SPACE  &mt LCTRL TAB  &mt LSHFT BSPC  &caps_word                                                         &kp BSPC   &mt RSHFT LEFT  &mt RCTRL DOWN  &mt LALT RIGHT  &mt RGUI ESC  &trans
 &trans           &kp GLOBE          &trans    &kp LS(TAB)   &mt GLOBE DEL      &trans  &trans  &trans  &trans  &trans  &trans         &trans    &trans  &mt RSHFT PG_UP   &mt RCTRL RET  &mt LALT PG_DN      &kp RGUI  &trans
 &trans              &trans          &trans         &trans          &trans              &trans  &trans   &to 0  &trans   &sl 9  &mt LSHFT RET                     &trans          &trans          &trans        &trans  &trans
            >;
        };

    };
};
